# Ij7vc_dom1_ecc_aggr19_REGS register map
Vendor: Texas Instruments
Peripheral module from a debugger description file (folder J721S2).
Registers are 32-bit, access not given, reset 0x0 unless marked. A register's access mark holds for its fields unless they carry their own. Offsets are as the file gives them; lines under a group give offsets from that group; [hi:lo] are bit positions; {n}, {i} and the like mark numbered series; 'fields as' and 'values as' point back to an identical list; <NAME> marks a mode.

## Ij7vc_dom1_ecc_aggr19_REGS
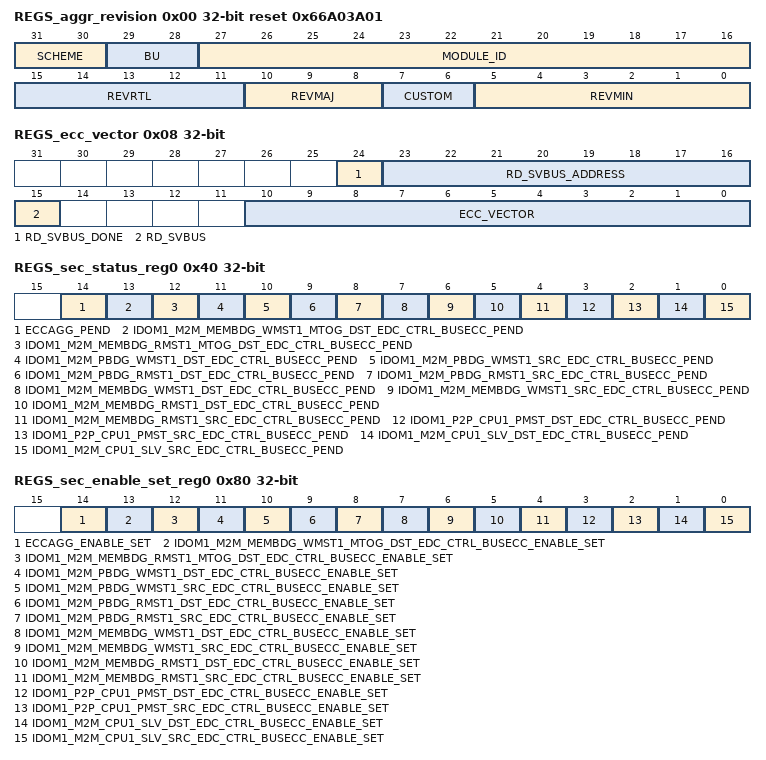
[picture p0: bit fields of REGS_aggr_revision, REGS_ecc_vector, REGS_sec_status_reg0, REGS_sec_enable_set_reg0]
0x00 REGS_aggr_revision ro reset 0x66A03A01 — Revision parameters
  [31:30] SCHEME
  [29:28] BU
  [27:16] MODULE_ID
  [15:11] REVRTL — RTL version
  [10:8] REVMAJ — Major version
  [7:6] CUSTOM — Custom version
  [5:0] REVMIN — Minor version
0x08 REGS_ecc_vector — ECC Vector Register
  [24] RD_SVBUS_DONE — Status to indicate if read on serial VBUS is complete, write of any value will clear this bit. (access R/W1TC)
  [23:16] RD_SVBUS_ADDRESS rw — Read address
  [15] RD_SVBUS — Write 1 to trigger a read on the serial VBUS (access R/W1TS)
  [10:0] ECC_VECTOR rw — Value written to select the corresponding ECC RAM for control or status
0x0C REGS_misc_status ro reset 0xF — Misc Status
  [10:0] NUM_RAMS — Indicates the number of RAMS serviced by the ECC aggregator
0x10 REGS_reserved_svbus rw — Reference other documents that contain the ECC RAM wrapper and EDC controller serial vbus register sets.
  [31:0] DATA — Serial VBUS register data
0x3C REGS_sec_eoi_reg — EOI Register
  [0] EOI_WR — EOI Register (access R/W1TS)
0x40 REGS_sec_status_reg0 — Interrupt Status Register 0
  [14] ECCAGG_PEND — Interrupt Pending Status for eccagg_pend (access R/W1TS)
  [13] IDOM1_M2M_MEMBDG_WMST1_MTOG_DST_EDC_CTRL_BUSECC_PEND — Interrupt Pending Status for Idom1_m2m_membdg_wmst1_mtog_dst_edc_ctrl_busecc_pend (access R/W1TS)
  [12] IDOM1_M2M_MEMBDG_RMST1_MTOG_DST_EDC_CTRL_BUSECC_PEND — Interrupt Pending Status for Idom1_m2m_membdg_rmst1_mtog_dst_edc_ctrl_busecc_pend (access R/W1TS)
  [11] IDOM1_M2M_PBDG_WMST1_DST_EDC_CTRL_BUSECC_PEND — Interrupt Pending Status for Idom1_m2m_pbdg_wmst1_dst_edc_ctrl_busecc_pend (access R/W1TS)
  [10] IDOM1_M2M_PBDG_WMST1_SRC_EDC_CTRL_BUSECC_PEND — Interrupt Pending Status for Idom1_m2m_pbdg_wmst1_src_edc_ctrl_busecc_pend (access R/W1TS)
  [9] IDOM1_M2M_PBDG_RMST1_DST_EDC_CTRL_BUSECC_PEND — Interrupt Pending Status for Idom1_m2m_pbdg_rmst1_dst_edc_ctrl_busecc_pend (access R/W1TS)
  [8] IDOM1_M2M_PBDG_RMST1_SRC_EDC_CTRL_BUSECC_PEND — Interrupt Pending Status for Idom1_m2m_pbdg_rmst1_src_edc_ctrl_busecc_pend (access R/W1TS)
  [7] IDOM1_M2M_MEMBDG_WMST1_DST_EDC_CTRL_BUSECC_PEND — Interrupt Pending Status for Idom1_m2m_membdg_wmst1_dst_edc_ctrl_busecc_pend (access R/W1TS)
  [6] IDOM1_M2M_MEMBDG_WMST1_SRC_EDC_CTRL_BUSECC_PEND — Interrupt Pending Status for Idom1_m2m_membdg_wmst1_src_edc_ctrl_busecc_pend (access R/W1TS)
  [5] IDOM1_M2M_MEMBDG_RMST1_DST_EDC_CTRL_BUSECC_PEND — Interrupt Pending Status for Idom1_m2m_membdg_rmst1_dst_edc_ctrl_busecc_pend (access R/W1TS)
  [4] IDOM1_M2M_MEMBDG_RMST1_SRC_EDC_CTRL_BUSECC_PEND — Interrupt Pending Status for Idom1_m2m_membdg_rmst1_src_edc_ctrl_busecc_pend (access R/W1TS)
  [3] IDOM1_P2P_CPU1_PMST_DST_EDC_CTRL_BUSECC_PEND — Interrupt Pending Status for Idom1_p2p_cpu1_pmst_dst_edc_ctrl_busecc_pend (access R/W1TS)
  [2] IDOM1_P2P_CPU1_PMST_SRC_EDC_CTRL_BUSECC_PEND — Interrupt Pending Status for Idom1_p2p_cpu1_pmst_src_edc_ctrl_busecc_pend (access R/W1TS)
  [1] IDOM1_M2M_CPU1_SLV_DST_EDC_CTRL_BUSECC_PEND — Interrupt Pending Status for Idom1_m2m_cpu1_slv_dst_edc_ctrl_busecc_pend (access R/W1TS)
  [0] IDOM1_M2M_CPU1_SLV_SRC_EDC_CTRL_BUSECC_PEND — Interrupt Pending Status for Idom1_m2m_cpu1_slv_src_edc_ctrl_busecc_pend (access R/W1TS)
0x80 REGS_sec_enable_set_reg0 — Interrupt Enable Set Register 0
  [14] ECCAGG_ENABLE_SET — Interrupt Enable Set Register for eccagg_pend (access R/W1TS)
  [13] IDOM1_M2M_MEMBDG_WMST1_MTOG_DST_EDC_CTRL_BUSECC_ENABLE_SET — Interrupt Enable Set Register for Idom1_m2m_membdg_wmst1_mtog_dst_edc_ctrl_busecc_pend (access R/W1TS)
  [12] IDOM1_M2M_MEMBDG_RMST1_MTOG_DST_EDC_CTRL_BUSECC_ENABLE_SET — Interrupt Enable Set Register for Idom1_m2m_membdg_rmst1_mtog_dst_edc_ctrl_busecc_pend (access R/W1TS)
  [11] IDOM1_M2M_PBDG_WMST1_DST_EDC_CTRL_BUSECC_ENABLE_SET — Interrupt Enable Set Register for Idom1_m2m_pbdg_wmst1_dst_edc_ctrl_busecc_pend (access R/W1TS)
  [10] IDOM1_M2M_PBDG_WMST1_SRC_EDC_CTRL_BUSECC_ENABLE_SET — Interrupt Enable Set Register for Idom1_m2m_pbdg_wmst1_src_edc_ctrl_busecc_pend (access R/W1TS)
  [9] IDOM1_M2M_PBDG_RMST1_DST_EDC_CTRL_BUSECC_ENABLE_SET — Interrupt Enable Set Register for Idom1_m2m_pbdg_rmst1_dst_edc_ctrl_busecc_pend (access R/W1TS)
  [8] IDOM1_M2M_PBDG_RMST1_SRC_EDC_CTRL_BUSECC_ENABLE_SET — Interrupt Enable Set Register for Idom1_m2m_pbdg_rmst1_src_edc_ctrl_busecc_pend (access R/W1TS)
  [7] IDOM1_M2M_MEMBDG_WMST1_DST_EDC_CTRL_BUSECC_ENABLE_SET — Interrupt Enable Set Register for Idom1_m2m_membdg_wmst1_dst_edc_ctrl_busecc_pend (access R/W1TS)
  [6] IDOM1_M2M_MEMBDG_WMST1_SRC_EDC_CTRL_BUSECC_ENABLE_SET — Interrupt Enable Set Register for Idom1_m2m_membdg_wmst1_src_edc_ctrl_busecc_pend (access R/W1TS)
  [5] IDOM1_M2M_MEMBDG_RMST1_DST_EDC_CTRL_BUSECC_ENABLE_SET — Interrupt Enable Set Register for Idom1_m2m_membdg_rmst1_dst_edc_ctrl_busecc_pend (access R/W1TS)
  [4] IDOM1_M2M_MEMBDG_RMST1_SRC_EDC_CTRL_BUSECC_ENABLE_SET — Interrupt Enable Set Register for Idom1_m2m_membdg_rmst1_src_edc_ctrl_busecc_pend (access R/W1TS)
  [3] IDOM1_P2P_CPU1_PMST_DST_EDC_CTRL_BUSECC_ENABLE_SET — Interrupt Enable Set Register for Idom1_p2p_cpu1_pmst_dst_edc_ctrl_busecc_pend (access R/W1TS)
  [2] IDOM1_P2P_CPU1_PMST_SRC_EDC_CTRL_BUSECC_ENABLE_SET — Interrupt Enable Set Register for Idom1_p2p_cpu1_pmst_src_edc_ctrl_busecc_pend (access R/W1TS)
  [1] IDOM1_M2M_CPU1_SLV_DST_EDC_CTRL_BUSECC_ENABLE_SET — Interrupt Enable Set Register for Idom1_m2m_cpu1_slv_dst_edc_ctrl_busecc_pend (access R/W1TS)
  [0] IDOM1_M2M_CPU1_SLV_SRC_EDC_CTRL_BUSECC_ENABLE_SET — Interrupt Enable Set Register for Idom1_m2m_cpu1_slv_src_edc_ctrl_busecc_pend (access R/W1TS)
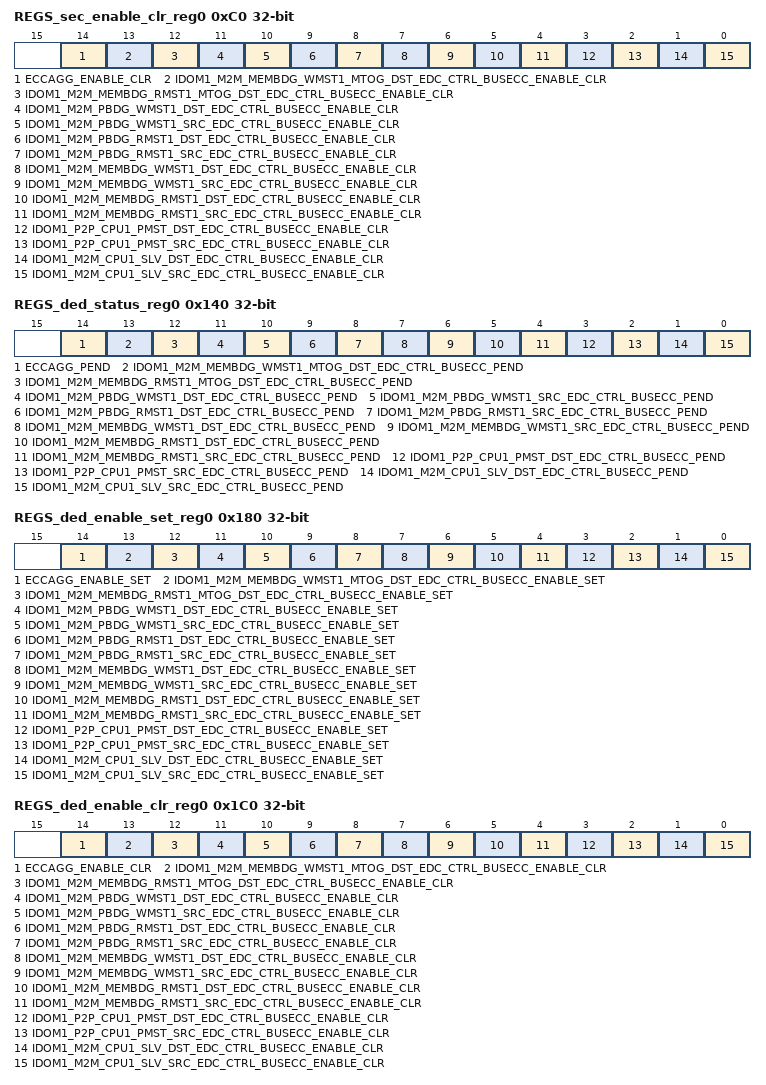
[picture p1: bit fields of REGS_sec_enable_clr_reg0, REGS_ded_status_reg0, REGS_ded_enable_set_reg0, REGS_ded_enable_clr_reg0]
0xC0 REGS_sec_enable_clr_reg0 — Interrupt Enable Clear Register 0
  [14] ECCAGG_ENABLE_CLR — Interrupt Enable Clear Register for eccagg_pend (access R/W1TC)
  [13] IDOM1_M2M_MEMBDG_WMST1_MTOG_DST_EDC_CTRL_BUSECC_ENABLE_CLR — Interrupt Enable Clear Register for Idom1_m2m_membdg_wmst1_mtog_dst_edc_ctrl_busecc_pend (access R/W1TC)
  [12] IDOM1_M2M_MEMBDG_RMST1_MTOG_DST_EDC_CTRL_BUSECC_ENABLE_CLR — Interrupt Enable Clear Register for Idom1_m2m_membdg_rmst1_mtog_dst_edc_ctrl_busecc_pend (access R/W1TC)
  [11] IDOM1_M2M_PBDG_WMST1_DST_EDC_CTRL_BUSECC_ENABLE_CLR — Interrupt Enable Clear Register for Idom1_m2m_pbdg_wmst1_dst_edc_ctrl_busecc_pend (access R/W1TC)
  [10] IDOM1_M2M_PBDG_WMST1_SRC_EDC_CTRL_BUSECC_ENABLE_CLR — Interrupt Enable Clear Register for Idom1_m2m_pbdg_wmst1_src_edc_ctrl_busecc_pend (access R/W1TC)
  [9] IDOM1_M2M_PBDG_RMST1_DST_EDC_CTRL_BUSECC_ENABLE_CLR — Interrupt Enable Clear Register for Idom1_m2m_pbdg_rmst1_dst_edc_ctrl_busecc_pend (access R/W1TC)
  [8] IDOM1_M2M_PBDG_RMST1_SRC_EDC_CTRL_BUSECC_ENABLE_CLR — Interrupt Enable Clear Register for Idom1_m2m_pbdg_rmst1_src_edc_ctrl_busecc_pend (access R/W1TC)
  [7] IDOM1_M2M_MEMBDG_WMST1_DST_EDC_CTRL_BUSECC_ENABLE_CLR — Interrupt Enable Clear Register for Idom1_m2m_membdg_wmst1_dst_edc_ctrl_busecc_pend (access R/W1TC)
  [6] IDOM1_M2M_MEMBDG_WMST1_SRC_EDC_CTRL_BUSECC_ENABLE_CLR — Interrupt Enable Clear Register for Idom1_m2m_membdg_wmst1_src_edc_ctrl_busecc_pend (access R/W1TC)
  [5] IDOM1_M2M_MEMBDG_RMST1_DST_EDC_CTRL_BUSECC_ENABLE_CLR — Interrupt Enable Clear Register for Idom1_m2m_membdg_rmst1_dst_edc_ctrl_busecc_pend (access R/W1TC)
  [4] IDOM1_M2M_MEMBDG_RMST1_SRC_EDC_CTRL_BUSECC_ENABLE_CLR — Interrupt Enable Clear Register for Idom1_m2m_membdg_rmst1_src_edc_ctrl_busecc_pend (access R/W1TC)
  [3] IDOM1_P2P_CPU1_PMST_DST_EDC_CTRL_BUSECC_ENABLE_CLR — Interrupt Enable Clear Register for Idom1_p2p_cpu1_pmst_dst_edc_ctrl_busecc_pend (access R/W1TC)
  [2] IDOM1_P2P_CPU1_PMST_SRC_EDC_CTRL_BUSECC_ENABLE_CLR — Interrupt Enable Clear Register for Idom1_p2p_cpu1_pmst_src_edc_ctrl_busecc_pend (access R/W1TC)
  [1] IDOM1_M2M_CPU1_SLV_DST_EDC_CTRL_BUSECC_ENABLE_CLR — Interrupt Enable Clear Register for Idom1_m2m_cpu1_slv_dst_edc_ctrl_busecc_pend (access R/W1TC)
  [0] IDOM1_M2M_CPU1_SLV_SRC_EDC_CTRL_BUSECC_ENABLE_CLR — Interrupt Enable Clear Register for Idom1_m2m_cpu1_slv_src_edc_ctrl_busecc_pend (access R/W1TC)
0x13C REGS_ded_eoi_reg — EOI Register
  [0] EOI_WR — EOI Register (access R/W1TS)
0x140 REGS_ded_status_reg0 — Interrupt Status Register 0
  fields as REGS_sec_status_reg0
0x180 REGS_ded_enable_set_reg0 — Interrupt Enable Set Register 0
  fields as REGS_sec_enable_set_reg0
0x1C0 REGS_ded_enable_clr_reg0 — Interrupt Enable Clear Register 0
  fields as REGS_sec_enable_clr_reg0
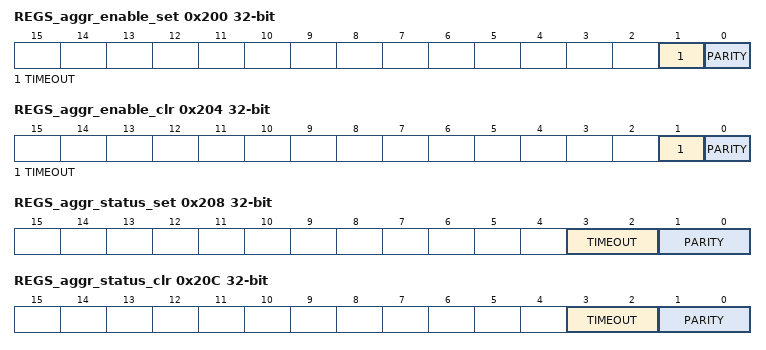
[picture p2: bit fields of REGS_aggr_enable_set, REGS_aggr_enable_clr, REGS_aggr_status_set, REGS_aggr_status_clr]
0x200 REGS_aggr_enable_set — AGGR interrupt enable set Register
  [1] TIMEOUT — interrupt enable set for svbus timeout errors (access R/W1TS)
  [0] PARITY — interrupt enable set for parity errors (access R/W1TS)
0x204 REGS_aggr_enable_clr — AGGR interrupt enable clear Register
  [1] TIMEOUT — interrupt enable clear for svbus timeout errors (access R/W1TC)
  [0] PARITY — interrupt enable clear for parity errors (access R/W1TC)
0x208 REGS_aggr_status_set — AGGR interrupt status set Register
  [3:2] TIMEOUT — interrupt status set for svbus timeout errors (access R/WI)
  [1:0] PARITY — interrupt status set for parity errors (access R/WI)
0x20C REGS_aggr_status_clr — AGGR interrupt status clear Register
  [3:2] TIMEOUT — interrupt status clear for svbus timeout errors (access R/WD)
  [1:0] PARITY — interrupt status clear for parity errors (access R/WD)
